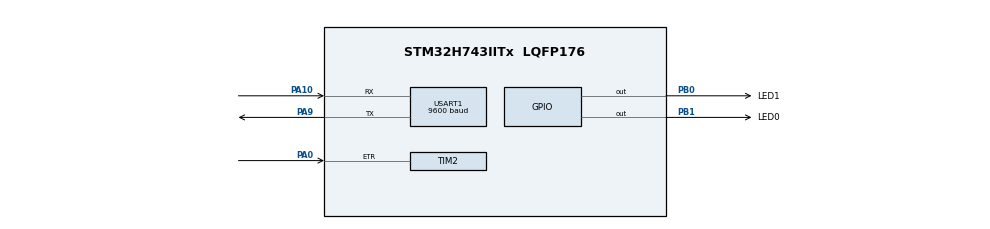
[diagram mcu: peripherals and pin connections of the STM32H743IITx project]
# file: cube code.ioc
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Mcu.Family=STM32H7
Mcu.Name=STM32H743IITx
Mcu.Package=LQFP176
NVIC.PriorityGroup=NVIC_PRIORITYGROUP_4
NVIC.TIM3_IRQn=true\:0\:0\:false\:false\:true\:true\:true
PA0.Signal=S_TIM2_ETR
PA10.Mode=Asynchronous
PA10.Signal=USART1_RX
PA9.Mode=Asynchronous
PA9.Signal=USART1_TX
PB0.GPIO_Label=LED1
PB0.GPIO_Speed=GPIO_SPEED_FREQ_HIGH
PB0.Signal=GPIO_Output
PB1.GPIO_Label=LED0
PB1.GPIO_Speed=GPIO_SPEED_FREQ_HIGH
PB1.Signal=GPIO_Output
PC14-OSC32_IN\ (OSC32_IN).Mode=LSE-External-Oscillator
PC14-OSC32_IN\ (OSC32_IN).Signal=RCC_OSC32_IN
PC15-OSC32_OUT\ (OSC32_OUT).Mode=LSE-External-Oscillator
PC15-OSC32_OUT\ (OSC32_OUT).Signal=RCC_OSC32_OUT
ProjectManager.HeapSize=0x200
ProjectManager.StackSize=0x400
ProjectManager.TargetToolchain=MDK-ARM V5.27
RCC.ADCFreq_Value=129000000
RCC.APB1Freq_Value=100000000
RCC.APB2Freq_Value=100000000
RCC.APB3Freq_Value=100000000
RCC.APB4Freq_Value=100000000
RCC.CortexFreq_Value=400000000
RCC.D1PPRE=RCC_APB3_DIV2
RCC.D2PPRE1=RCC_APB1_DIV2
RCC.D2PPRE2=RCC_APB2_DIV2
RCC.D3PPRE=RCC_APB4_DIV2
RCC.DIVM1=4
RCC.DIVN1=50
RCC.HCLKFreq_Value=200000000
RCC.HPRE=RCC_HCLK_DIV2
RCC.PLL2FRACN=0
RCC.PLL3FRACN=0
RCC.PLLFRACN=0
RCC.SYSCLKFreq_VALUE=400000000
RCC.SYSCLKSource=RCC_SYSCLKSOURCE_PLLCLK
RCC.USBFreq_Value=400000000
SH.S_TIM2_ETR.0=TIM2_ETR,ClockSourceETR_Mode2
TIM2.Period=0xFFFFFFFF
TIM3.AutoReloadPreload=TIM_AUTORELOAD_PRELOAD_ENABLE
TIM3.Period=10000
TIM3.Prescaler=20000
USART1.BaudRate=9600
USART1.VirtualMode-Asynchronous=VM_ASYNC
VP_TIM3_VS_ClockSourceINT.Mode=Internal
board=custom

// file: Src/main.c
/* USER CODE BEGIN Header */
/**
  ******************************************************************************
  * @file           : main.c
  * @brief          : Main program body
  ******************************************************************************
  * @attention
  *
  * <h2><center>&copy; Copyright (c) 2020 STMicroelectronics.
  * All rights reserved.</center></h2>
  *
  * This software component is licensed by ST under BSD 3-Clause license,
  * the "License"; You may not use this file except in compliance with the
  * License. You may obtain a copy of the License at:
  *                        opensource.org/licenses/BSD-3-Clause
  *
  ******************************************************************************
  */
/* USER CODE END Header */

#include "main.h"
#include "tim.h"
#include "usart.h"
#include "gpio.h"

/* USER CODE BEGIN PV */
	unsigned long int count=0;
/* USER CODE END PV */

void SystemClock_Config(void);

/* USER CODE BEGIN 0 */
#ifdef __GNUC__
#define PUTCHAR_PROTOTYPE int __io_putchar(int ch)
#else
#define PUTCHAR_PROTOTYPE int fputc(int ch, FILE *f)
#endif
PUTCHAR_PROTOTYPE
{
HAL_UART_Transmit(&huart1 , (uint8_t *)&ch, 1, 0xFFFF);
return ch;
}

/* USER CODE END 0 */

int main(void)
{

  /* MCU Configuration--------------------------------------------------------*/

  /* Reset of all peripherals, Initializes the Flash interface and the Systick. */
  HAL_Init();

  /* Configure the system clock */
  SystemClock_Config();

  /* Initialize all configured peripherals */
  MX_GPIO_Init();
  MX_TIM2_Init();
  MX_TIM3_Init();
  MX_USART1_UART_Init();
  /* USER CODE BEGIN 2 */
	HAL_TIM_Base_Start_IT(&htim3);
	HAL_TIM_Base_Start(&htim2);
  /* USER CODE END 2 */

  /* Infinite loop */
  while (1)
  {

    /* USER CODE BEGIN 3 */
		printf("%ld\r\n",count-count/1000*47);
		HAL_Delay(500);
  }
  /* USER CODE END 3 */
}

void SystemClock_Config(void)
{
  RCC_OscInitTypeDef RCC_OscInitStruct = {0};
  RCC_ClkInitTypeDef RCC_ClkInitStruct = {0};
  RCC_PeriphCLKInitTypeDef PeriphClkInitStruct = {0};

  /** Supply configuration update enable
  */
  HAL_PWREx_ConfigSupply(PWR_LDO_SUPPLY);
  /** Configure the main internal regulator output voltage
  */
  __HAL_PWR_VOLTAGESCALING_CONFIG(PWR_REGULATOR_VOLTAGE_SCALE1);

  while(!__HAL_PWR_GET_FLAG(PWR_FLAG_VOSRDY)) {}
  /** Initializes the CPU, AHB and APB busses clocks
  */
  RCC_OscInitStruct.OscillatorType = RCC_OSCILLATORTYPE_HSI;
  RCC_OscInitStruct.HSIState = RCC_HSI_DIV1;
  RCC_OscInitStruct.HSICalibrationValue = RCC_HSICALIBRATION_DEFAULT;
  RCC_OscInitStruct.PLL.PLLState = RCC_PLL_ON;
  RCC_OscInitStruct.PLL.PLLSource = RCC_PLLSOURCE_HSI;
  RCC_OscInitStruct.PLL.PLLM = 4;
  RCC_OscInitStruct.PLL.PLLN = 50;
  RCC_OscInitStruct.PLL.PLLP = 2;
  RCC_OscInitStruct.PLL.PLLQ = 2;
  RCC_OscInitStruct.PLL.PLLR = 2;
  RCC_OscInitStruct.PLL.PLLRGE = RCC_PLL1VCIRANGE_3;
  RCC_OscInitStruct.PLL.PLLVCOSEL = RCC_PLL1VCOWIDE;
  RCC_OscInitStruct.PLL.PLLFRACN = 0;
  if (HAL_RCC_OscConfig(&RCC_OscInitStruct) != HAL_OK)
  {
    Error_Handler();
  }
  /** Initializes the CPU, AHB and APB busses clocks
  */
  RCC_ClkInitStruct.ClockType = RCC_CLOCKTYPE_HCLK|RCC_CLOCKTYPE_SYSCLK
                              |RCC_CLOCKTYPE_PCLK1|RCC_CLOCKTYPE_PCLK2
                              |RCC_CLOCKTYPE_D3PCLK1|RCC_CLOCKTYPE_D1PCLK1;
  RCC_ClkInitStruct.SYSCLKSource = RCC_SYSCLKSOURCE_PLLCLK;
  RCC_ClkInitStruct.SYSCLKDivider = RCC_SYSCLK_DIV1;
  RCC_ClkInitStruct.AHBCLKDivider = RCC_HCLK_DIV2;
  RCC_ClkInitStruct.APB3CLKDivider = RCC_APB3_DIV2;
  RCC_ClkInitStruct.APB1CLKDivider = RCC_APB1_DIV2;
  RCC_ClkInitStruct.APB2CLKDivider = RCC_APB2_DIV2;
  RCC_ClkInitStruct.APB4CLKDivider = RCC_APB4_DIV2;

  if (HAL_RCC_ClockConfig(&RCC_ClkInitStruct, FLASH_LATENCY_2) != HAL_OK)
  {
    Error_Handler();
  }
  PeriphClkInitStruct.PeriphClockSelection = RCC_PERIPHCLK_USART1;
  PeriphClkInitStruct.Usart16ClockSelection = RCC_USART16CLKSOURCE_D2PCLK2;
  if (HAL_RCCEx_PeriphCLKConfig(&PeriphClkInitStruct) != HAL_OK)
  {
    Error_Handler();
  }
}

void Error_Handler(void)
{
}

/************************ (C) COPYRIGHT STMicroelectronics *****END OF FILE****/
